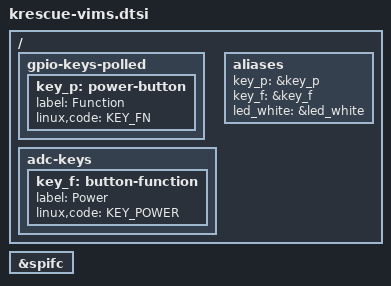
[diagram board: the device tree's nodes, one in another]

// common VIMS

/ {

gpio-keys-polled {
    key_p: power-button {
    };
};

adc-keys {
    key_f: button-function {
    };
};

aliases {
    key_p = &key_p;
    key_f = &key_f;
    led_white = &led_white;
//  spifc = &spifc;
};

};

&key_p {
    label = "Function";
    linux,code = <KEY_FN>;
};

&key_f {
    label = "Power";
    linux,code = <KEY_POWER>;
};

&spifc {
    status = "okay";
};
